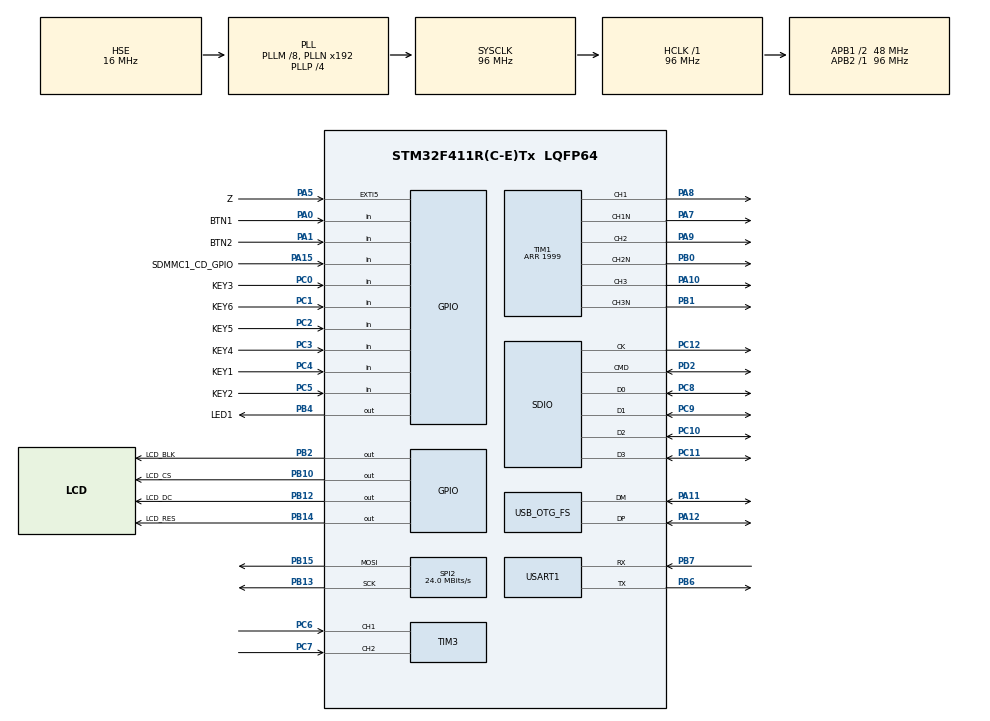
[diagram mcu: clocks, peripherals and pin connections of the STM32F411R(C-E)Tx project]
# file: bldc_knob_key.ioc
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Dma.Request0=USART1_RX
Dma.Request1=SDIO_RX
Dma.Request2=SDIO_TX
Dma.Request3=SPI2_TX
Dma.SDIO_RX.1.Direction=DMA_PERIPH_TO_MEMORY
Dma.SDIO_RX.1.FIFOMode=DMA_FIFOMODE_ENABLE
Dma.SDIO_RX.1.FIFOThreshold=DMA_FIFO_THRESHOLD_FULL
Dma.SDIO_RX.1.Instance=DMA2_Stream3
Dma.SDIO_RX.1.MemBurst=DMA_MBURST_INC4
Dma.SDIO_RX.1.MemDataAlignment=DMA_MDATAALIGN_WORD
Dma.SDIO_RX.1.MemInc=DMA_MINC_ENABLE
Dma.SDIO_RX.1.Mode=DMA_PFCTRL
Dma.SDIO_RX.1.PeriphBurst=DMA_PBURST_INC4
Dma.SDIO_RX.1.PeriphDataAlignment=DMA_PDATAALIGN_WORD
Dma.SDIO_RX.1.PeriphInc=DMA_PINC_DISABLE
Dma.SDIO_RX.1.Priority=DMA_PRIORITY_LOW
Dma.SDIO_TX.2.Direction=DMA_MEMORY_TO_PERIPH
Dma.SDIO_TX.2.FIFOMode=DMA_FIFOMODE_ENABLE
Dma.SDIO_TX.2.FIFOThreshold=DMA_FIFO_THRESHOLD_FULL
Dma.SDIO_TX.2.Instance=DMA2_Stream6
Dma.SDIO_TX.2.MemBurst=DMA_MBURST_INC4
Dma.SDIO_TX.2.MemDataAlignment=DMA_MDATAALIGN_WORD
Dma.SDIO_TX.2.MemInc=DMA_MINC_ENABLE
Dma.SDIO_TX.2.Mode=DMA_PFCTRL
Dma.SDIO_TX.2.PeriphBurst=DMA_PBURST_INC4
Dma.SDIO_TX.2.PeriphDataAlignment=DMA_PDATAALIGN_WORD
Dma.SDIO_TX.2.PeriphInc=DMA_PINC_DISABLE
Dma.SDIO_TX.2.Priority=DMA_PRIORITY_LOW
Dma.SPI2_TX.3.Direction=DMA_MEMORY_TO_PERIPH
Dma.SPI2_TX.3.FIFOMode=DMA_FIFOMODE_DISABLE
Dma.SPI2_TX.3.Instance=DMA1_Stream4
Dma.SPI2_TX.3.MemDataAlignment=DMA_MDATAALIGN_HALFWORD
Dma.SPI2_TX.3.MemInc=DMA_MINC_ENABLE
Dma.SPI2_TX.3.Mode=DMA_NORMAL
Dma.SPI2_TX.3.PeriphDataAlignment=DMA_PDATAALIGN_HALFWORD
Dma.SPI2_TX.3.PeriphInc=DMA_PINC_DISABLE
Dma.SPI2_TX.3.Priority=DMA_PRIORITY_LOW
Dma.USART1_RX.0.Direction=DMA_PERIPH_TO_MEMORY
Dma.USART1_RX.0.FIFOMode=DMA_FIFOMODE_DISABLE
Dma.USART1_RX.0.Instance=DMA2_Stream2
Dma.USART1_RX.0.MemDataAlignment=DMA_MDATAALIGN_BYTE
Dma.USART1_RX.0.MemInc=DMA_MINC_ENABLE
Dma.USART1_RX.0.Mode=DMA_CIRCULAR
Dma.USART1_RX.0.PeriphDataAlignment=DMA_PDATAALIGN_BYTE
Dma.USART1_RX.0.PeriphInc=DMA_PINC_DISABLE
Dma.USART1_RX.0.Priority=DMA_PRIORITY_LOW
FATFS.BSP.number=1
FATFS.USE_DMA_CODE_SD=1
FATFS._USE_LFN=1
FATFS0.BSP.STBoard=false
FATFS0.BSP.api=Unknown
FATFS0.BSP.instance=PA15
FATFS0.BSP.ip=GPIO
FATFS0.BSP.mode=Input
FATFS0.BSP.name=Detect_SDIO
FATFS0.BSP.solution=PA15
Mcu.Family=STM32F4
Mcu.Name=STM32F411R(C-E)Tx
Mcu.Package=LQFP64
NVIC.DMA1_Stream4_IRQn=true\:8\:0\:true\:false\:true\:false\:true\:true
NVIC.DMA2_Stream2_IRQn=true\:5\:0\:true\:false\:true\:false\:true\:true
NVIC.DMA2_Stream3_IRQn=true\:5\:0\:true\:false\:true\:false\:true\:true
NVIC.DMA2_Stream6_IRQn=true\:5\:0\:true\:false\:true\:false\:true\:true
NVIC.EXTI9_5_IRQn=true\:9\:0\:true\:false\:true\:true\:true\:true
NVIC.OTG_FS_IRQn=true\:7\:0\:true\:false\:true\:true\:true\:true
NVIC.PriorityGroup=NVIC_PRIORITYGROUP_4
NVIC.SDIO_IRQn=true\:5\:0\:true\:false\:true\:true\:true\:true
NVIC.SPI2_IRQn=true\:8\:0\:true\:false\:true\:true\:true\:true
NVIC.TIM1_UP_TIM10_IRQn=true\:0\:0\:false\:false\:true\:true\:true\:true
NVIC.USART1_IRQn=true\:5\:0\:true\:false\:true\:true\:true\:true
PA0-WKUP.GPIO_Label=BTN1
PA0-WKUP.Signal=GPIO_Input
PA1.GPIO_Label=BTN2
PA1.Signal=GPIO_Input
PA10.Signal=S_TIM1_CH3
PA11.Mode=Device_Only
PA11.Signal=USB_OTG_FS_DM
PA12.Mode=Device_Only
PA12.Signal=USB_OTG_FS_DP
PA13.Mode=Serial_Wire
PA13.Signal=SYS_JTMS-SWDIO
PA14.Mode=Serial_Wire
PA14.Signal=SYS_JTCK-SWCLK
PA15.GPIO_Label=SDMMC1_CD_GPIO
PA15.Signal=GPIO_Input
PA2.Signal=S_TIM2_CH3
PA5.GPIO_Label=Z
PA5.GPIO_ModeDefaultEXTI=GPIO_MODE_IT_FALLING
PA5.Signal=GPXTI5
PA7.Mode=PWM Generation1 CH1 CH1N
PA7.Signal=TIM1_CH1N
PA8.Signal=S_TIM1_CH1
PA9.Signal=S_TIM1_CH2
PB0.Mode=PWM Generation2 CH2 CH2N
PB0.Signal=TIM1_CH2N
PB1.Mode=PWM Generation3 CH3 CH3N
PB1.Signal=TIM1_CH3N
PB10.GPIO_Label=LCD_CS
PB10.Signal=GPIO_Output
PB12.GPIO_Label=LCD_DC
PB12.Signal=GPIO_Output
PB13.Mode=TX_Only_Simplex_Unidirect_Master
PB13.Signal=SPI2_SCK
PB14.GPIO_Label=LCD_RES
PB14.Signal=GPIO_Output
PB15.Mode=TX_Only_Simplex_Unidirect_Master
PB15.Signal=SPI2_MOSI
PB2.GPIO_Label=LCD_BLK
PB2.Signal=GPIO_Output
PB4.GPIO_Label=LED1
PB4.PinState=GPIO_PIN_SET
PB4.Signal=GPIO_Output
PB6.Mode=Asynchronous
PB6.Signal=USART1_TX
PB7.Mode=Asynchronous
PB7.Signal=USART1_RX
PB8.Signal=I2C1_SCL
PB9.Signal=I2C1_SDA
PC0.GPIO_Label=KEY3
PC0.Signal=GPIO_Input
PC1.GPIO_Label=KEY6
PC1.Signal=GPIO_Input
PC10.GPIO_PuPd=GPIO_PULLUP
PC10.GPIO_Speed_High_Default=GPIO_SPEED_FREQ_LOW
PC10.Mode=SD_4_bits_Wide_bus
PC10.Signal=SDIO_D2
PC11.GPIO_PuPd=GPIO_PULLUP
PC11.GPIO_Speed_High_Default=GPIO_SPEED_FREQ_LOW
PC11.Mode=SD_4_bits_Wide_bus
PC11.Signal=SDIO_D3
PC12.GPIO_Speed_High_Default=GPIO_SPEED_FREQ_LOW
PC12.Mode=SD_4_bits_Wide_bus
PC12.Signal=SDIO_CK
PC2.GPIO_Label=KEY5
PC2.Signal=GPIO_Input
PC3.GPIO_Label=KEY4
PC3.Signal=GPIO_Input
PC4.GPIO_Label=KEY1
PC4.Signal=GPIO_Input
PC5.GPIO_Label=KEY2
PC5.Signal=GPIO_Input
PC6.Signal=S_TIM3_CH1
PC7.Signal=S_TIM3_CH2
PC8.GPIO_PuPd=GPIO_PULLUP
PC8.GPIO_Speed_High_Default=GPIO_SPEED_FREQ_LOW
PC8.Mode=SD_4_bits_Wide_bus
PC8.Signal=SDIO_D0
PC9.GPIO_PuPd=GPIO_PULLUP
PC9.GPIO_Speed_High_Default=GPIO_SPEED_FREQ_LOW
PC9.Mode=SD_4_bits_Wide_bus
PC9.Signal=SDIO_D1
PD2.GPIO_PuPd=GPIO_PULLUP
PD2.GPIO_Speed_High_Default=GPIO_SPEED_FREQ_LOW
PD2.Mode=SD_4_bits_Wide_bus
PD2.Signal=SDIO_CMD
PH0\ -\ OSC_IN.Mode=HSE-External-Oscillator
PH0\ -\ OSC_IN.Signal=RCC_OSC_IN
PH1\ -\ OSC_OUT.Mode=HSE-External-Oscillator
PH1\ -\ OSC_OUT.Signal=RCC_OSC_OUT
ProjectManager.HeapSize=0x2000
ProjectManager.StackSize=0x2000
ProjectManager.TargetToolchain=STM32CubeIDE
RCC.48MHZClocksFreq_Value=48000000
RCC.AHBFreq_Value=96000000
RCC.APB1CLKDivider=RCC_HCLK_DIV2
RCC.APB1Freq_Value=48000000
RCC.APB1TimFreq_Value=96000000
RCC.APB2Freq_Value=96000000
RCC.APB2TimFreq_Value=96000000
RCC.CortexFreq_Value=96000000
RCC.HCLKFreq_Value=96000000
RCC.HSE_VALUE=16000000
RCC.HSI_VALUE=16000000
RCC.LSE_VALUE=32768
RCC.PLLM=8
RCC.PLLP=RCC_PLLP_DIV4
RCC.PLLQ=8
RCC.SYSCLKFreq_VALUE=96000000
RCC.SYSCLKSource=RCC_SYSCLKSOURCE_PLLCLK
RCC.VCOOutputFreq_Value=384000000
SDIO.ClockDiv=2
SH.S_TIM1_CH1.0=TIM1_CH1,PWM Generation1 CH1 CH1N
SH.S_TIM1_CH2.0=TIM1_CH2,PWM Generation2 CH2 CH2N
SH.S_TIM1_CH3.0=TIM1_CH3,PWM Generation3 CH3 CH3N
SH.S_TIM2_CH3.0=TIM2_CH3
SH.S_TIM3_CH1.0=TIM3_CH1,Encoder_Interface
SH.S_TIM3_CH2.0=TIM3_CH2,Encoder_Interface
SPI2.BaudRatePrescaler=SPI_BAUDRATEPRESCALER_2
SPI2.CalculateBaudRate=24.0 MBits/s
SPI2.Direction=SPI_DIRECTION_2LINES
SPI2.Mode=SPI_MODE_MASTER
SPI2.VirtualType=VM_MASTER
TIM1.AutoReloadPreload=TIM_AUTORELOAD_PRELOAD_ENABLE
TIM1.Channel-PWM\ Generation1\ CH1\ CH1N=TIM_CHANNEL_1
TIM1.Channel-PWM\ Generation2\ CH2\ CH2N=TIM_CHANNEL_2
TIM1.Channel-PWM\ Generation3\ CH3\ CH3N=TIM_CHANNEL_3
TIM1.CounterMode=TIM_COUNTERMODE_CENTERALIGNED1
TIM1.DeadTime=50
TIM1.Period=1999
TIM10.AutoReloadPreload=TIM_AUTORELOAD_PRELOAD_ENABLE
TIM10.Period=999
TIM10.Prescaler=95
TIM3.EncoderMode=TIM_ENCODERMODE_TI12
TIM3.IC1Filter=8
TIM3.IC2Filter=8
USART1.VirtualMode=VM_ASYNC
USB_DEVICE.APP_RX_DATA_SIZE=1024
USB_DEVICE.APP_TX_DATA_SIZE=1024
USB_DEVICE.CLASS_NAME_FS=CDC
USB_DEVICE.VirtualMode=Cdc
USB_DEVICE.VirtualModeFS=Cdc_FS
USB_OTG_FS.Sof_enable=ENABLE
USB_OTG_FS.VirtualMode=Device_Only
VP_FATFS_VS_SDIO.Mode=SDIO
VP_TIM10_VS_ClockSourceINT.Mode=Enable_Timer
VP_USB_DEVICE_VS_USB_DEVICE_CDC_FS.Mode=CDC_FS
board=custom

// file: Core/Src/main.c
/* USER CODE BEGIN Header */
/**
  ******************************************************************************
  * @file           : main.c
  * @brief          : Main program body
  ******************************************************************************
  * @attention
  *
  * Copyright (c) 2026 STMicroelectronics.
  * All rights reserved.
  *
  * This software is licensed under terms that can be found in the LICENSE file
  * in the root directory of this software component.
  * If no LICENSE file comes with this software, it is provided AS-IS.
  *
  ******************************************************************************
  */
/* USER CODE END Header */
#include "main.h"
#include "fatfs.h"

/* USER CODE BEGIN Includes */
#include "ap.h"
/* USER CODE END Includes */

SD_HandleTypeDef hsd;
DMA_HandleTypeDef hdma_sdio_rx;
DMA_HandleTypeDef hdma_sdio_tx;

SPI_HandleTypeDef hspi2;
DMA_HandleTypeDef hdma_spi2_tx;

TIM_HandleTypeDef htim1;
TIM_HandleTypeDef htim3;
TIM_HandleTypeDef htim10;

UART_HandleTypeDef huart1;
DMA_HandleTypeDef hdma_usart1_rx;

void SystemClock_Config(void);
static void MX_GPIO_Init(void);
static void MX_DMA_Init(void);
static void MX_TIM1_Init(void);
static void MX_SDIO_SD_Init(void);
static void MX_SPI2_Init(void);
static void MX_USART1_UART_Init(void);
static void MX_TIM3_Init(void);
static void MX_TIM10_Init(void);

int main(void)
{

  /* MCU Configuration--------------------------------------------------------*/

  /* Reset of all peripherals, Initializes the Flash interface and the Systick. */
  HAL_Init();

  /* Configure the system clock */
  SystemClock_Config();

  /* Initialize all configured peripherals */
  MX_GPIO_Init();
  MX_DMA_Init();
  MX_TIM1_Init();
  MX_SDIO_SD_Init();
  MX_SPI2_Init();
  MX_USART1_UART_Init();
  MX_TIM3_Init();
  MX_FATFS_Init();
  MX_TIM10_Init();
  /* USER CODE BEGIN 2 */
  hwInit();

  apInit();
  apMain();
  /* USER CODE END 2 */

  /* Infinite loop */
  while (1)
  {

  }
}

void SystemClock_Config(void)
{
  RCC_OscInitTypeDef RCC_OscInitStruct = {0};
  RCC_ClkInitTypeDef RCC_ClkInitStruct = {0};

  /** Configure the main internal regulator output voltage
  */
  __HAL_RCC_PWR_CLK_ENABLE();
  __HAL_PWR_VOLTAGESCALING_CONFIG(PWR_REGULATOR_VOLTAGE_SCALE1);

  /** Initializes the RCC Oscillators according to the specified parameters
  * in the RCC_OscInitTypeDef structure.
  */
  RCC_OscInitStruct.OscillatorType = RCC_OSCILLATORTYPE_HSE;
  RCC_OscInitStruct.HSEState = RCC_HSE_ON;
  RCC_OscInitStruct.PLL.PLLState = RCC_PLL_ON;
  RCC_OscInitStruct.PLL.PLLSource = RCC_PLLSOURCE_HSE;
  RCC_OscInitStruct.PLL.PLLM = 8;
  RCC_OscInitStruct.PLL.PLLN = 192;
  RCC_OscInitStruct.PLL.PLLP = RCC_PLLP_DIV4;
  RCC_OscInitStruct.PLL.PLLQ = 8;
  if (HAL_RCC_OscConfig(&RCC_OscInitStruct) != HAL_OK)
  {
    Error_Handler();
  }

  /** Initializes the CPU, AHB and APB buses clocks
  */
  RCC_ClkInitStruct.ClockType = RCC_CLOCKTYPE_HCLK|RCC_CLOCKTYPE_SYSCLK
                              |RCC_CLOCKTYPE_PCLK1|RCC_CLOCKTYPE_PCLK2;
  RCC_ClkInitStruct.SYSCLKSource = RCC_SYSCLKSOURCE_PLLCLK;
  RCC_ClkInitStruct.AHBCLKDivider = RCC_SYSCLK_DIV1;
  RCC_ClkInitStruct.APB1CLKDivider = RCC_HCLK_DIV2;
  RCC_ClkInitStruct.APB2CLKDivider = RCC_HCLK_DIV1;

  if (HAL_RCC_ClockConfig(&RCC_ClkInitStruct, FLASH_LATENCY_3) != HAL_OK)
  {
    Error_Handler();
  }
}

static void MX_SDIO_SD_Init(void)
{

  hsd.Instance = SDIO;
  hsd.Init.ClockEdge = SDIO_CLOCK_EDGE_RISING;
  hsd.Init.ClockBypass = SDIO_CLOCK_BYPASS_DISABLE;
  hsd.Init.ClockPowerSave = SDIO_CLOCK_POWER_SAVE_DISABLE;
  hsd.Init.BusWide = SDIO_BUS_WIDE_4B;
  hsd.Init.HardwareFlowControl = SDIO_HARDWARE_FLOW_CONTROL_DISABLE;
  hsd.Init.ClockDiv = 2;
  /* USER CODE BEGIN SDIO_Init 2 */
  hsd.Init.BusWide = SDIO_BUS_WIDE_1B;
  /* USER CODE END SDIO_Init 2 */

}

static void MX_SPI2_Init(void)
{

  /* SPI2 parameter configuration*/
  hspi2.Instance = SPI2;
  hspi2.Init.Mode = SPI_MODE_MASTER;
  hspi2.Init.Direction = SPI_DIRECTION_2LINES;
  hspi2.Init.DataSize = SPI_DATASIZE_8BIT;
  hspi2.Init.CLKPolarity = SPI_POLARITY_LOW;
  hspi2.Init.CLKPhase = SPI_PHASE_1EDGE;
  hspi2.Init.NSS = SPI_NSS_SOFT;
  hspi2.Init.BaudRatePrescaler = SPI_BAUDRATEPRESCALER_2;
  hspi2.Init.FirstBit = SPI_FIRSTBIT_MSB;
  hspi2.Init.TIMode = SPI_TIMODE_DISABLE;
  hspi2.Init.CRCCalculation = SPI_CRCCALCULATION_DISABLE;
  hspi2.Init.CRCPolynomial = 10;
  if (HAL_SPI_Init(&hspi2) != HAL_OK)
  {
    Error_Handler();
  }

}

static void MX_TIM1_Init(void)
{

  TIM_MasterConfigTypeDef sMasterConfig = {0};
  TIM_OC_InitTypeDef sConfigOC = {0};
  TIM_BreakDeadTimeConfigTypeDef sBreakDeadTimeConfig = {0};

  htim1.Instance = TIM1;
  htim1.Init.Prescaler = 0;
  htim1.Init.CounterMode = TIM_COUNTERMODE_CENTERALIGNED1;
  htim1.Init.Period = 1999;
  htim1.Init.ClockDivision = TIM_CLOCKDIVISION_DIV1;
  htim1.Init.RepetitionCounter = 0;
  htim1.Init.AutoReloadPreload = TIM_AUTORELOAD_PRELOAD_ENABLE;
  if (HAL_TIM_PWM_Init(&htim1) != HAL_OK)
  {
    Error_Handler();
  }
  sMasterConfig.MasterOutputTrigger = TIM_TRGO_RESET;
  sMasterConfig.MasterSlaveMode = TIM_MASTERSLAVEMODE_DISABLE;
  if (HAL_TIMEx_MasterConfigSynchronization(&htim1, &sMasterConfig) != HAL_OK)
  {
    Error_Handler();
  }
  sConfigOC.OCMode = TIM_OCMODE_PWM1;
  sConfigOC.Pulse = 0;
  sConfigOC.OCPolarity = TIM_OCPOLARITY_HIGH;
  sConfigOC.OCNPolarity = TIM_OCNPOLARITY_HIGH;
  sConfigOC.OCFastMode = TIM_OCFAST_DISABLE;
  sConfigOC.OCIdleState = TIM_OCIDLESTATE_RESET;
  sConfigOC.OCNIdleState = TIM_OCNIDLESTATE_RESET;
  if (HAL_TIM_PWM_ConfigChannel(&htim1, &sConfigOC, TIM_CHANNEL_1) != HAL_OK)
  {
    Error_Handler();
  }
  if (HAL_TIM_PWM_ConfigChannel(&htim1, &sConfigOC, TIM_CHANNEL_2) != HAL_OK)
  {
    Error_Handler();
  }
  if (HAL_TIM_PWM_ConfigChannel(&htim1, &sConfigOC, TIM_CHANNEL_3) != HAL_OK)
  {
    Error_Handler();
  }
  sBreakDeadTimeConfig.OffStateRunMode = TIM_OSSR_DISABLE;
  sBreakDeadTimeConfig.OffStateIDLEMode = TIM_OSSI_DISABLE;
  sBreakDeadTimeConfig.LockLevel = TIM_LOCKLEVEL_OFF;
  sBreakDeadTimeConfig.DeadTime = 50;
  sBreakDeadTimeConfig.BreakState = TIM_BREAK_DISABLE;
  sBreakDeadTimeConfig.BreakPolarity = TIM_BREAKPOLARITY_HIGH;
  sBreakDeadTimeConfig.AutomaticOutput = TIM_AUTOMATICOUTPUT_DISABLE;
  if (HAL_TIMEx_ConfigBreakDeadTime(&htim1, &sBreakDeadTimeConfig) != HAL_OK)
  {
    Error_Handler();
  }
  HAL_TIM_MspPostInit(&htim1);

}

static void MX_TIM3_Init(void)
{

  TIM_Encoder_InitTypeDef sConfig = {0};
  TIM_MasterConfigTypeDef sMasterConfig = {0};

  htim3.Instance = TIM3;
  htim3.Init.Prescaler = 0;
  htim3.Init.CounterMode = TIM_COUNTERMODE_UP;
  htim3.Init.Period = 65535;
  htim3.Init.ClockDivision = TIM_CLOCKDIVISION_DIV1;
  htim3.Init.AutoReloadPreload = TIM_AUTORELOAD_PRELOAD_DISABLE;
  sConfig.EncoderMode = TIM_ENCODERMODE_TI12;
  sConfig.IC1Polarity = TIM_ICPOLARITY_RISING;
  sConfig.IC1Selection = TIM_ICSELECTION_DIRECTTI;
  sConfig.IC1Prescaler = TIM_ICPSC_DIV1;
  sConfig.IC1Filter = 8;
  sConfig.IC2Polarity = TIM_ICPOLARITY_RISING;
  sConfig.IC2Selection = TIM_ICSELECTION_DIRECTTI;
  sConfig.IC2Prescaler = TIM_ICPSC_DIV1;
  sConfig.IC2Filter = 8;
  if (HAL_TIM_Encoder_Init(&htim3, &sConfig) != HAL_OK)
  {
    Error_Handler();
  }
  sMasterConfig.MasterOutputTrigger = TIM_TRGO_RESET;
  sMasterConfig.MasterSlaveMode = TIM_MASTERSLAVEMODE_DISABLE;
  if (HAL_TIMEx_MasterConfigSynchronization(&htim3, &sMasterConfig) != HAL_OK)
  {
    Error_Handler();
  }

}

static void MX_TIM10_Init(void)
{

  htim10.Instance = TIM10;
  htim10.Init.Prescaler = 95;
  htim10.Init.CounterMode = TIM_COUNTERMODE_UP;
  htim10.Init.Period = 999;
  htim10.Init.ClockDivision = TIM_CLOCKDIVISION_DIV1;
  htim10.Init.AutoReloadPreload = TIM_AUTORELOAD_PRELOAD_ENABLE;
  if (HAL_TIM_Base_Init(&htim10) != HAL_OK)
  {
    Error_Handler();
  }

}

static void MX_USART1_UART_Init(void)
{

  huart1.Instance = USART1;
  huart1.Init.BaudRate = 115200;
  huart1.Init.WordLength = UART_WORDLENGTH_8B;
  huart1.Init.StopBits = UART_STOPBITS_1;
  huart1.Init.Parity = UART_PARITY_NONE;
  huart1.Init.Mode = UART_MODE_TX_RX;
  huart1.Init.HwFlowCtl = UART_HWCONTROL_NONE;
  huart1.Init.OverSampling = UART_OVERSAMPLING_16;
  if (HAL_UART_Init(&huart1) != HAL_OK)
  {
    Error_Handler();
  }

}

static void MX_DMA_Init(void)
{

  /* DMA controller clock enable */
  __HAL_RCC_DMA2_CLK_ENABLE();
  __HAL_RCC_DMA1_CLK_ENABLE();

  /* DMA interrupt init */
  /* DMA1_Stream4_IRQn interrupt configuration */
  HAL_NVIC_SetPriority(DMA1_Stream4_IRQn, 8, 0);
  HAL_NVIC_EnableIRQ(DMA1_Stream4_IRQn);
  /* DMA2_Stream2_IRQn interrupt configuration */
  HAL_NVIC_SetPriority(DMA2_Stream2_IRQn, 5, 0);
  HAL_NVIC_EnableIRQ(DMA2_Stream2_IRQn);
  /* DMA2_Stream3_IRQn interrupt configuration */
  HAL_NVIC_SetPriority(DMA2_Stream3_IRQn, 5, 0);
  HAL_NVIC_EnableIRQ(DMA2_Stream3_IRQn);
  /* DMA2_Stream6_IRQn interrupt configuration */
  HAL_NVIC_SetPriority(DMA2_Stream6_IRQn, 5, 0);
  HAL_NVIC_EnableIRQ(DMA2_Stream6_IRQn);

}

static void MX_GPIO_Init(void)
{
  GPIO_InitTypeDef GPIO_InitStruct = {0};

  /* GPIO Ports Clock Enable */
  __HAL_RCC_GPIOH_CLK_ENABLE();
  __HAL_RCC_GPIOC_CLK_ENABLE();
  __HAL_RCC_GPIOA_CLK_ENABLE();
  __HAL_RCC_GPIOB_CLK_ENABLE();
  __HAL_RCC_GPIOD_CLK_ENABLE();

  /*Configure GPIO pin Output Level */
  HAL_GPIO_WritePin(GPIOB, LCD_BLK_Pin|LCD_CS_Pin|LCD_DC_Pin|LCD_RES_Pin, GPIO_PIN_RESET);

  /*Configure GPIO pin Output Level */
  HAL_GPIO_WritePin(LED1_GPIO_Port, LED1_Pin, GPIO_PIN_SET);

  /*Configure GPIO pins : KEY3_Pin KEY6_Pin KEY5_Pin KEY4_Pin
                           KEY1_Pin KEY2_Pin */
  GPIO_InitStruct.Pin = KEY3_Pin|KEY6_Pin|KEY5_Pin|KEY4_Pin
                          |KEY1_Pin|KEY2_Pin;
  GPIO_InitStruct.Mode = GPIO_MODE_INPUT;
  GPIO_InitStruct.Pull = GPIO_NOPULL;
  HAL_GPIO_Init(GPIOC, &GPIO_InitStruct);

  /*Configure GPIO pins : BTN1_Pin BTN2_Pin SDMMC1_CD_GPIO_Pin */
  GPIO_InitStruct.Pin = BTN1_Pin|BTN2_Pin|SDMMC1_CD_GPIO_Pin;
  GPIO_InitStruct.Mode = GPIO_MODE_INPUT;
  GPIO_InitStruct.Pull = GPIO_NOPULL;
  HAL_GPIO_Init(GPIOA, &GPIO_InitStruct);

  /*Configure GPIO pin : PA2 */
  GPIO_InitStruct.Pin = GPIO_PIN_2;
  GPIO_InitStruct.Mode = GPIO_MODE_AF_PP;
  GPIO_InitStruct.Pull = GPIO_NOPULL;
  GPIO_InitStruct.Speed = GPIO_SPEED_FREQ_LOW;
  GPIO_InitStruct.Alternate = GPIO_AF1_TIM2;
  HAL_GPIO_Init(GPIOA, &GPIO_InitStruct);

  /*Configure GPIO pin : Z_Pin */
  GPIO_InitStruct.Pin = Z_Pin;
  GPIO_InitStruct.Mode = GPIO_MODE_IT_FALLING;
  GPIO_InitStruct.Pull = GPIO_NOPULL;
  HAL_GPIO_Init(Z_GPIO_Port, &GPIO_InitStruct);

  /*Configure GPIO pins : LCD_BLK_Pin LCD_CS_Pin LCD_DC_Pin LCD_RES_Pin
                           LED1_Pin */
  GPIO_InitStruct.Pin = LCD_BLK_Pin|LCD_CS_Pin|LCD_DC_Pin|LCD_RES_Pin
                          |LED1_Pin;
  GPIO_InitStruct.Mode = GPIO_MODE_OUTPUT_PP;
  GPIO_InitStruct.Pull = GPIO_NOPULL;
  GPIO_InitStruct.Speed = GPIO_SPEED_FREQ_LOW;
  HAL_GPIO_Init(GPIOB, &GPIO_InitStruct);

  /*Configure GPIO pins : PB8 PB9 */
  GPIO_InitStruct.Pin = GPIO_PIN_8|GPIO_PIN_9;
  GPIO_InitStruct.Mode = GPIO_MODE_AF_OD;
  GPIO_InitStruct.Pull = GPIO_NOPULL;
  GPIO_InitStruct.Speed = GPIO_SPEED_FREQ_VERY_HIGH;
  GPIO_InitStruct.Alternate = GPIO_AF4_I2C1;
  HAL_GPIO_Init(GPIOB, &GPIO_InitStruct);

  /* EXTI interrupt init*/
  HAL_NVIC_SetPriority(EXTI9_5_IRQn, 9, 0);
  HAL_NVIC_EnableIRQ(EXTI9_5_IRQn);

}

void Error_Handler(void)
{
  __disable_irq();
  while (1)
  {
  }
}
